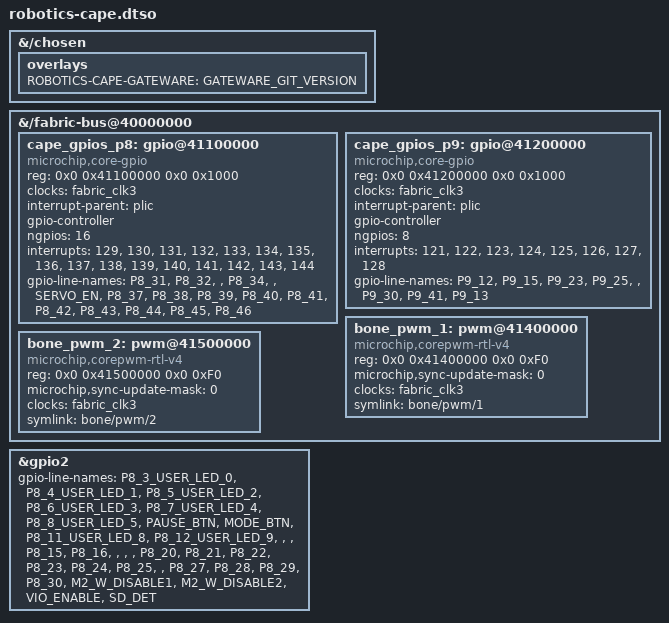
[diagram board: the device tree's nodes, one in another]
// SPDX-License-Identifier: (GPL-2.0 OR MIT)
/* Copyright (c) 2023 Microchip Technology Inc */

/dts-v1/;
/plugin/;

&{/chosen} {
	overlays {
		ROBOTICS-CAPE-GATEWARE = "GATEWARE_GIT_VERSION";
	};
};

&{/fabric-bus@40000000} {
	#address-cells = <2>;
	#size-cells = <2>;

	cape_gpios_p8: gpio@41100000 {
		compatible = "microchip,core-gpio", "microchip,coregpio-rtl-v3";
		reg = <0x0 0x41100000 0x0 0x1000>;
		clocks = <&fabric_clk3>;
		interrupt-parent = <&plic>;
		gpio-controller;
		#gpio-cells = <2>;
		ngpios = <16>;
		status = "okay";
		interrupts = <129>, <130>, <131>, <132>,
			     <133>, <134>, <135>, <136>,
			     <137>, <138>, <139>, <140>,
			     <141>, <142>, <143>, <144>;

		gpio-line-names = "P8_31", "P8_32", "", "P8_34",
				  "", "SERVO_EN", "P8_37", "P8_38",
				  "P8_39", "P8_40", "P8_41", "P8_42",
				  "P8_43", "P8_44", "P8_45", "P8_46";
	};

	cape_gpios_p9: gpio@41200000 {
		compatible = "microchip,core-gpio", "microchip,coregpio-rtl-v3";
		reg = <0x0 0x41200000 0x0 0x1000>;
		clocks = <&fabric_clk3>;
		interrupt-parent = <&plic>;
		gpio-controller;
		#gpio-cells = <2>;
		ngpios = <8>;
		status = "okay";
		interrupts = <121>, <122>, <123>, <124>,
			     <125>, <126>, <127>, <128>;

		gpio-line-names = "P9_12", "P9_15", "P9_23", "P9_25",
				  "", "P9_30", "P9_41", "P9_13";
	};

	bone_pwm_1: pwm@41400000 {
		compatible = "microchip,corepwm-rtl-v4";
		reg = <0x0 0x41400000 0x0 0xF0>;
		microchip,sync-update-mask = /bits/ 32 <0>;
		#pwm-cells = <3>;
		status = "okay";
		clocks = <&fabric_clk3>;
		symlink = "bone/pwm/1";
	};

	bone_pwm_2: pwm@41500000 {
		compatible = "microchip,corepwm-rtl-v4";
		reg = <0x0 0x41500000 0x0 0xF0>;
		microchip,sync-update-mask = /bits/ 32 <0>;
		#pwm-cells = <3>;
		status = "okay";
		clocks = <&fabric_clk3>;
		symlink = "bone/pwm/2";
	};
};

&gpio2 {
	gpio-line-names = "P8_3_USER_LED_0", "P8_4_USER_LED_1", "P8_5_USER_LED_2",
			  "P8_6_USER_LED_3", "P8_7_USER_LED_4", "P8_8_USER_LED_5",
			  "PAUSE_BTN", "MODE_BTN", "P8_11_USER_LED_8",
			  "P8_12_USER_LED_9", "", "",
			  "P8_15", "P8_16", "", "", "",
			  "P8_20", "P8_21", "P8_22", "P8_23", "P8_24",
			  "P8_25", "", "P8_27", "P8_28", "P8_29",
			  "P8_30",
			  "M2_W_DISABLE1", "M2_W_DISABLE2",
			  "VIO_ENABLE", "SD_DET";
};
